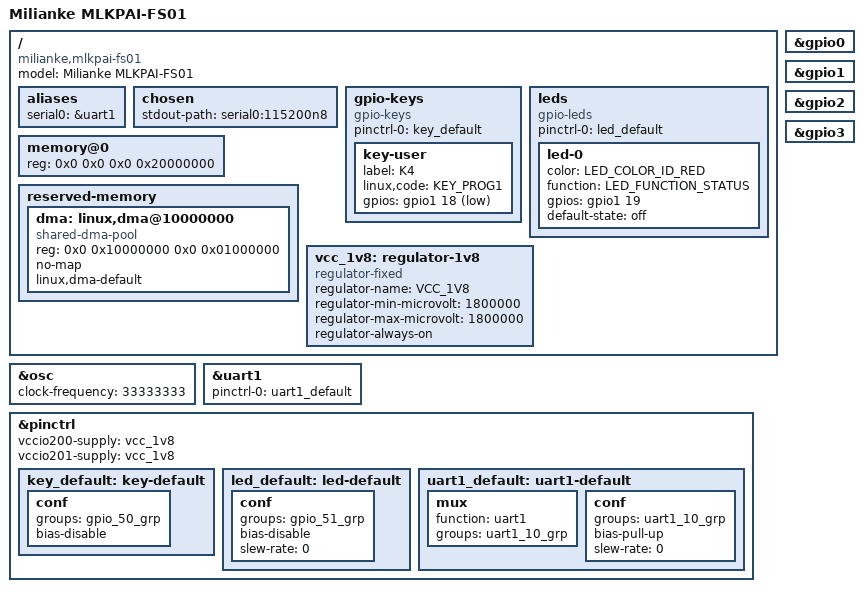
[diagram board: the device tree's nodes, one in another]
// SPDX-License-Identifier: GPL-2.0 OR MIT
/*
 * Copyright (C) 2025 Junhui Liu <junhui.liu@pigmoral.tech>
 */

#include <dt-bindings/gpio/gpio.h>
#include <dt-bindings/input/input.h>
#include <dt-bindings/leds/common.h>

#include "dr1v90.dtsi"

/ {
	model = "Milianke MLKPAI-FS01";
	compatible = "milianke,mlkpai-fs01", "anlogic,dr1v90";

	aliases {
		serial0 = &uart1;
	};

	chosen {
		stdout-path = "serial0:115200n8";
	};

	gpio-keys {
		compatible = "gpio-keys";
		pinctrl-names = "default";
		pinctrl-0 = <&key_default>;

		key-user {
			label = "K4";
			linux,code = <KEY_PROG1>;
			gpios = <&gpio1 18 GPIO_ACTIVE_LOW>;
		};
	};

	leds {
		compatible = "gpio-leds";
		pinctrl-names = "default";
		pinctrl-0 = <&led_default>;

		led-0 {
			color = <LED_COLOR_ID_RED>;
			function = LED_FUNCTION_STATUS;
			gpios = <&gpio1 19 GPIO_ACTIVE_HIGH>;
			default-state = "off";
		};
	};

	memory@0 {
		device_type = "memory";
		reg = <0x0 0x0 0x0 0x20000000>;
	};

	reserved-memory {
		#address-cells = <2>;
		#size-cells = <2>;
		ranges;

		dma: linux,dma@10000000 {
			compatible = "shared-dma-pool";
			reg = <0x0 0x10000000 0x0 0x01000000>;
			no-map;
			linux,dma-default;
		};
	};

	vcc_1v8: regulator-1v8 {
		compatible = "regulator-fixed";
		regulator-name = "VCC_1V8";
		regulator-min-microvolt = <1800000>;
		regulator-max-microvolt = <1800000>;
		regulator-always-on;
	};
};

&gpio0 {
	status = "okay";
};

&gpio1 {
	status = "okay";
};

&gpio2 {
	status = "okay";
};

&gpio3 {
	status = "okay";
};

&osc {
	clock-frequency = <33333333>;
};

&uart1 {
	pinctrl-names = "default";
	pinctrl-0 = <&uart1_default>;
	status = "okay";
};

&pinctrl {
	vccio200-supply = <&vcc_1v8>;
	vccio201-supply = <&vcc_1v8>;

	key_default: key-default {
		conf {
			groups = "gpio_50_grp";
			bias-disable;
		};
	};

	led_default: led-default {
		conf {
			groups = "gpio_51_grp";
			bias-disable;
			slew-rate = <0>;
		};
	};

	uart1_default: uart1-default {
		mux {
			function = "uart1";
			groups = "uart1_10_grp";
		};

		conf {
			groups = "uart1_10_grp";
			bias-pull-up;
			slew-rate = <0>;
		};
	};
};
